# S32K148_M4 register map
Vendor: NXP Semiconductors; File version: 1.1a
CPU: CM4 r0p1, little endian, MPU, FPU, VTOR, 4 interrupt priority bits
Registers are 32-bit, read-write, reset 0x0 unless marked. A register's access mark holds for its fields unless they carry their own. Offsets are from the block's base; [hi:lo] are bit positions; {n}, {i} and the like mark numbered series; 'fields as' and 'values as' point back to an identical list.

## QuadSPI
Base 0x40076000; register names take the prefix QuadSPI_
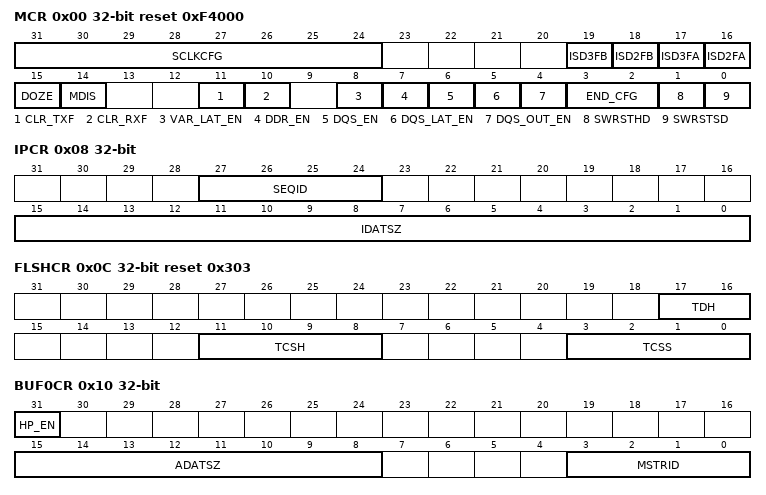
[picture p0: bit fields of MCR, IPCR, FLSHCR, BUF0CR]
0x00 MCR reset 0xF4000 — Module Configuration Register
  [31:24] SCLKCFG — Serial Clock Configuration
  [19] ISD3FB — Idle Signal Drive IOFB[3] Flash B
    0=IOFB[3] is driven to logic L; 1=IOFB[3] is driven to logic H
  [18] ISD2FB — Idle Signal Drive IOFB[2] Flash B
    0=IOFB[2] is driven to logic L; 1=IOFB[2] is driven to logic H
  [17] ISD3FA — Idle Signal Drive IOFA[3] Flash A
    0=IOFA[3] is driven to logic L; 1=IOFA[3] is driven to logic H
  [16] ISD2FA — Idle Signal Drive IOFA[2] Flash A
    0=IOFA[2] is driven to logic L; 1=IOFA[2] is driven to logic H
  [15] DOZE — Doze Enable
    0=A doze request will be ignored by the QuadSPI module; 1=A doze request will be processed by the QuadSPI module
  [14] MDIS — Module Disable
    0=Enable QuadSPI clocks; 1=Allow external logic to disable QuadSPI clocks
  [11] CLR_TXF — Clear TX FIFO/Buffer. Invalidates the TX Buffer content. This is a self-clearing field.
    0=No action; 1=Read and write pointers of the TX Buffer are reset to 0. QSPI_TBSR[TRCTR] is reset to 0.
  [10] CLR_RXF — Clear RX FIFO. Invalidates the RX Buffer. This is a self-clearing field.
    0=No action; 1=Read and write pointers of the RX Buffer are reset to 0. QSPI_RBSR[RDBFL] is reset to 0.
  [8] VAR_LAT_EN — This field is used to enable variable latency feature in the controller
    0=Fixed latency: Twice + 1 latency enable; 1=Variable latency: 'once' or 'twice + 1' the initial latency based on Data strobe during CA phase. If enabled also need to ensure QSPI_FLSHCR[TCSS] must be >= 2.
  [7] DDR_EN — DDR mode enable
    0=2x clock are disabled for SDR instructions only; 1=2x clock are enabled supports both SDR and DDR instruction
  [6] DQS_EN — DQS enable
    0=DQS disabled; 1=DQS enabled. When enabled, the incoming data is sampled on both the edges of DQS input when QSPI_MCR[DDR_EN] is set, else, on only one edge when QSPI_MCR[DDR_EN] is 0. The QSPI_SMPR[DDR_SMP] values are ignored.
  [5] DQS_LAT_EN — DQS Latency Enable
    0=DQS Latency disabled; 1=DQS feature with latency included enabled
  [4] DQS_OUT_EN — This field is valid when Data Strobe is also used as an output from controller during Write data phase
    0=DQS as an output from controller is disabled; 1=DQS as an output from controller is enabled
  [3:2] END_CFG — Defines the endianness of the QuadSPI module. For more details refer to Byte Ordering Endianess
  [1] SWRSTHD — Software reset for AHB domain
    0=No action; 1=AHB domain flops are reset. Does not reset configuration registers. It is advisable to reset both the serial flash domain and AHB domain at the same time. Resetting only one domain might lead to side effects. The software resets need the clock to be running to propagate to the design. The MCR[MDIS] should therefore be set to 0 when the software reset bits are asserted. Also, before they can be deasserted again (by setting MCR[SWRSTHD] to 0), it is recommended to set the MCR[MDIS] bit to 1. Once the software resets have been deasserted, the normal operation can be started by setting the MCR[MDIS] bit to 0.
  [0] SWRSTSD — Software reset for serial flash domain
    0=No action; 1=Serial Flash domain flops are reset. Does not reset configuration registers. It is advisable to reset both the serial flash domain and AHB domain at the same time. Resetting only one domain might lead to side effects. The software resets need the clock to be running to propagate to the design. The MCR[MDIS] should therefore be set to 0 when the software reset bits are asserted. Also, before they can be deasserted again (by setting MCR[SWRSTSD] to 0), it is recommended to set the MCR[MDIS] bit to 1. Once the software resets have been deasserted, the normal operation can be started by setting the MCR[MDIS] bit to 0.
0x08 IPCR — IP Configuration Register
  [27:24] SEQID — Points to a sequence in the Look-up table
  [15:0] IDATSZ — IP data transfer size. Defines the data transfer size in bytes of the IP command.
0x0C FLSHCR reset 0x303 — Flash Configuration Register
  [17:16] TDH — Serial flash data in hold time
    0=Data aligned with the posedge of Internal reference clock of QuadSPI; 1=Data aligned with 2x serial flash half clock
  [11:8] TCSH — Serial flash CS hold time in terms of serial flash clock cycles
  [3:0] TCSS — Serial flash CS setup time in terms of serial flash clock cycles
0x10 BUF0CR — Buffer0 Configuration Register
  [31] HP_EN — High Priority Enable
  [15:8] ADATSZ — AHB data transfer size
  [3:0] MSTRID — Master ID
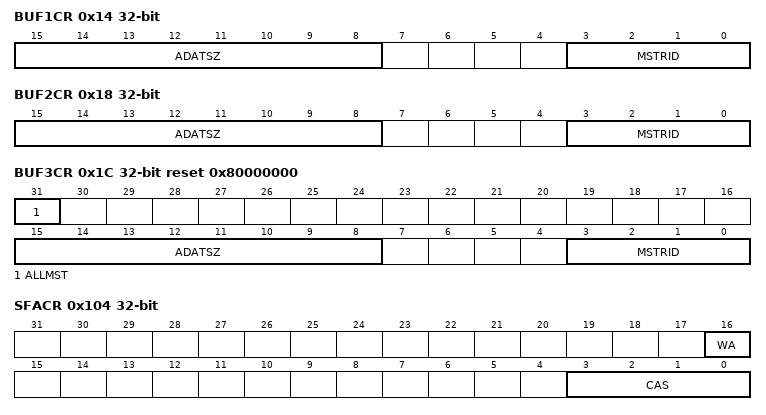
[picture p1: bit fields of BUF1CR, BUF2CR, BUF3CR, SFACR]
0x14 BUF1CR — Buffer1 Configuration Register
  [15:8] ADATSZ — AHB data transfer size
  [3:0] MSTRID — Master ID
0x18 BUF2CR — Buffer2 Configuration Register
  [15:8] ADATSZ — AHB data transfer size
  [3:0] MSTRID — Master ID
0x1C BUF3CR reset 0x80000000 — Buffer3 Configuration Register
  [31] ALLMST — All master enable
  [15:8] ADATSZ — AHB data transfer size
  [3:0] MSTRID — Master ID
0x20 BFGENCR — Buffer Generic Configuration Register
  [15:12] SEQID — Points to a sequence in the Look-up-table
0x24 SOCCR — SOC Configuration Register
  [31:0] SOCCFG — SOC Configuration For details, refer to chip-specific QuadSPI information.
{0x30+4i} BUF{i}IND (i=0..2) — Buffer{i} Top Index Register
  [31:3] TPINDX{i} — Top index of buffer {i}.
0x100 SFAR — Serial Flash Address Register
  [31:0] SFADR — Serial Flash Address. The register content is used as byte address for all following IP Commands.
0x104 SFACR — Serial Flash Address Configuration Register
  [16] WA — Word Addressable
    0=Byte addressable serial flash mode; 1=Word (2 byte) addressable serial flash mode
  [3:0] CAS — Column Address Space
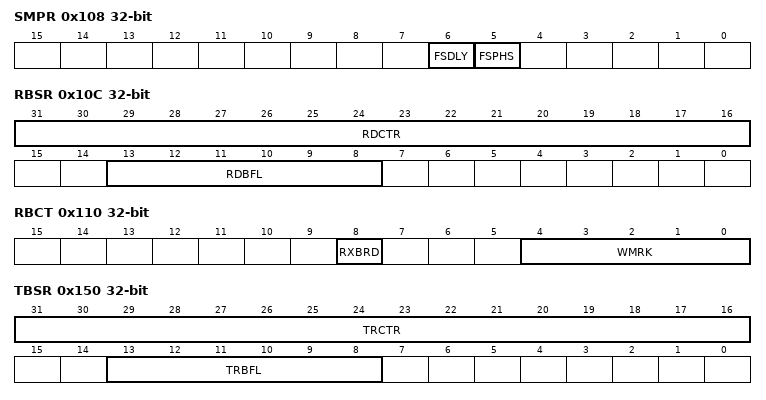
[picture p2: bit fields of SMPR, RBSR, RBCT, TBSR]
0x108 SMPR — Sampling Register
  [6] FSDLY — Full Speed Delay selection for SDR instructions. Select the delay with respect to the reference edge for the sample point valid for full speed commands.
    0=One clock cycle delay; 1=Two clock cycles delay
  [5] FSPHS — Full Speed Phase selection for SDR instructions.
    0=Select sampling at non-inverted clock; 1=Select sampling at inverted clock
0x10C RBSR ro — RX Buffer Status Register
  [31:16] RDCTR — Read Counter
  [13:8] RDBFL — RX Buffer Fill Level
0x110 RBCT — RX Buffer Control Register
  [8] RXBRD — RX Buffer Readout. This field specifies the access scheme for the RX Buffer readout.
    0=RX Buffer content is read using the AHB Bus registers QSPI_ARDB0 to QSPI_ARDB31; 1=RX Buffer content is read using the IP Bus registers QSPI_RBDR0 to QSPI_RBDR31
  [4:0] WMRK — RX Buffer Watermark
0x150 TBSR ro — TX Buffer Status Register
  [31:16] TRCTR — Transmit Counter
  [13:8] TRBFL — TX Buffer Fill Level
0x154 TBDR — TX Buffer Data Register
  [31:0] TXDATA — TX Data On write access the data is written into the next available entry of the TX Buffer and the QPSI_TBSR[TRBFL] field is updated accordingly
0x158 TBCT — Tx Buffer Control Register
  [4:0] WMRK — Determines the watermark for the TX Buffer
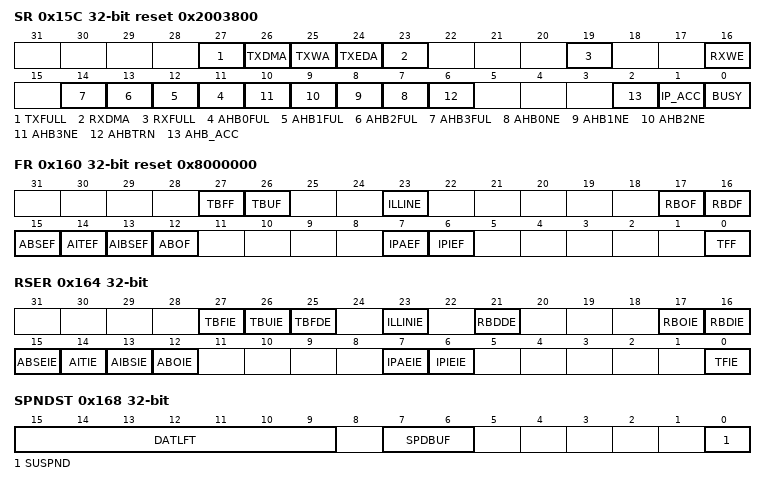
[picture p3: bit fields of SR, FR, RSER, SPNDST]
0x15C SR ro reset 0x2003800 — Status Register
  [27] TXFULL — TX Buffer Full. Asserted when no more data can be stored.
  [26] TXDMA
  [25] TXWA — TX Buffer watermark Available
  [24] TXEDA — Tx Buffer Enough Data Available
  [23] RXDMA — RX Buffer DMA. Asserted when RX Buffer read out via DMA is active i.e DMA is requested or running.
  [19] RXFULL — RX Buffer Full
  [16] RXWE — RX Buffer Watermark Exceeded
  [n+11] AHB{n}FUL (n=0..3) — AHB {n} Buffer Full. Asserted when AHB {n} buffer is full.
  [n+7] AHB{n}NE (n=0..3) — AHB {n} Buffer Not Empty. Asserted when AHB {n} buffer contains data.
  [6] AHBTRN — AHB Access Transaction pending
  [2] AHB_ACC — AHB Access. Asserted when the transaction currently executed was initiated by AHB bus.
  [1] IP_ACC — IP Access. Asserted when transaction currently executed was initiated by IP bus.
  [0] BUSY — Module Busy
0x160 FR reset 0x8000000 write-1-clears — Flag Register
  [27] TBFF write-1-clears — TX Buffer Fill Flag
  [26] TBUF write-1-clears — TX Buffer Underrun Flag
  [23] ILLINE write-1-clears — Illegal Instruction Error Flag
  [17] RBOF write-1-clears — RX Buffer Overflow Flag
  [16] RBDF write-1-clears — RX Buffer Drain Flag
  [15] ABSEF write-1-clears — AHB Sequence Error Flag
  [14] AITEF write-1-clears — AHB Illegal transaction error flag
  [13] AIBSEF write-1-clears — AHB Illegal Burst Size Error Flag
  [12] ABOF write-1-clears — AHB Buffer Overflow Flag
  [7] IPAEF write-1-clears — IP Command Trigger during AHB Access Error Flag
  [6] IPIEF write-1-clears — IP Command Trigger could not be executed Error Flag
  [0] TFF write-1-clears — IP Command Transaction Finished Flag
0x164 RSER — Interrupt and DMA Request Select and Enable Register
  [27] TBFIE — TX Buffer Fill Interrupt Enable
    0=No TBFF interrupt will be generated; 1=TBFF interrupt will be generated
  [26] TBUIE — TX Buffer Underrun Interrupt Enable
    0=No TBUF interrupt will be generated; 1=TBUF interrupt will be generated
  [25] TBFDE — TX Buffer Fill DMA Enable
    0=No DMA request will be generated; 1=DMA request will be generated
  [23] ILLINIE — Illegal Instruction Error Interrupt Enable. Triggered by ILLINE flag in QSPI_FR
    0=No ILLINE interrupt will be generated; 1=ILLINE interrupt will be generated
  [21] RBDDE — RX Buffer Drain DMA Enable: Enables generation of DMA requests for RX Buffer Drain
    values as TBFDE
  [17] RBOIE — RX Buffer Overflow Interrupt Enable
    0=No RBOF interrupt will be generated; 1=RBOF interrupt will be generated
  [16] RBDIE — RX Buffer Drain Interrupt Enable: Enables generation of IRQ requests for RX Buffer Drain
    0=No RBDF interrupt will be generated; 1=RBDF Interrupt will be generated
  [15] ABSEIE — AHB Sequence Error Interrupt Enable: Triggered by ABSEF flags of QSPI_FR
    0=No ABSEF interrupt will be generated; 1=ABSEF interrupt will be generated
  [14] AITIE — AHB Illegal transaction interrupt enable.
    0=No AITEF interrupt will be generated; 1=AITEF interrupt will be generated
  [13] AIBSIE — AHB Illegal Burst Size Interrupt Enable
    0=No AIBSEF interrupt will be generated; 1=AIBSEF interrupt will be generated
  [12] ABOIE — AHB Buffer Overflow Interrupt Enable
    0=No ABOF interrupt will be generated; 1=ABOF interrupt will be generated
  [7] IPAEIE — IP Command Trigger during AHB Access Error Interrupt Enable
    0=No IPAEF interrupt will be generated; 1=IPAEF interrupt will be generated
  [6] IPIEIE — IP Command Trigger during IP Access Error Interrupt Enable
    0=No IPIEF interrupt will be generated; 1=IPIEF interrupt will be generated
  [0] TFIE — Transaction Finished Interrupt Enable
    0=No TFF interrupt will be generated; 1=TFF interrupt will be generated
0x168 SPNDST ro — Sequence Suspend Status Register
  [15:9] DATLFT — Data left: Provides information about the amount of data left to be read in the suspended sequence
  [7:6] SPDBUF — Suspended Buffer: Provides the suspended buffer number. Valid only when SUSPND is set to 1'b1
  [0] SUSPND — When set, it signifies that a sequence is in suspended state
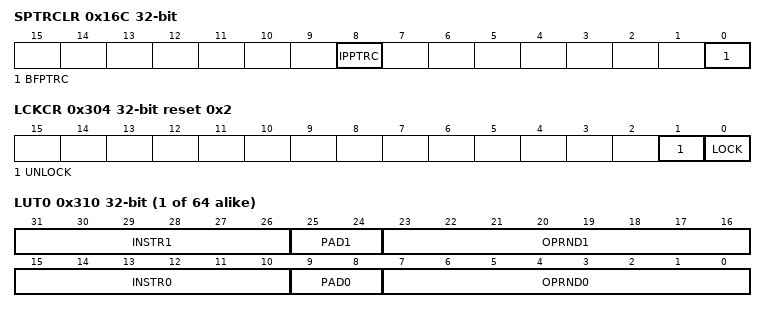
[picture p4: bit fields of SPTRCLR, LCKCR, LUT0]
0x16C SPTRCLR — Sequence Pointer Clear Register
  [8] IPPTRC — IP Pointer Clear: 1: Clears the sequence pointer for IP accesses as defined in QuadSPI_IPCR This is a self-clearing field
  [0] BFPTRC — Buffer Pointer Clear: 1: Clears the sequence pointer for AHB accesses as defined in QuadSPI_BFGENCR
0x180 SFA1AD — Serial Flash A1 Top Address
  [31:10] TPADA1 — Top address for Serial Flash A1. In effect, TPADxx is the first location of the next memory.
0x184 SFA2AD — Serial Flash A2 Top Address
  [31:10] TPADA2 — Top address for Serial Flash A2. In effect, TPxxAD is the first location of the next memory.
0x188 SFB1AD — Serial Flash B1 Top Address
  [31:10] TPADB1 — Top address for Serial Flash B1.In effect, TPxxAD is the first location of the next memory.
0x18C SFB2AD — Serial Flash B2 Top Address
  [31:10] TPADB2 — Top address for Serial Flash B2. In effect, TPxxAD is the first location of the next memory.
{0x200+4i} RBDR{i} (i=0..31) ro — RX Buffer Data Register
  [31:0] RXDATA
0x300 LUTKEY reset 0x5AF05AF0
  [31:0] KEY — The key to lock or unlock the LUT. The KEY is 0x5AF05AF0. The read value is always 0x5AF05AF0
0x304 LCKCR reset 0x2 — LUT Lock Configuration Register
  [1] UNLOCK — Unlocks the LUT when the following two conditions are met: 1
  [0] LOCK — Locks the LUT when the following condition is met: This register is written just after the LUTKEYLUT Key Register The LUT key register was written with 0x5AF05AF0 key
{0x310+4i} LUT{i} (i=0..63) — Look-up Table register
  [31:26] INSTR1 — Instruction 1
  [25:24] PAD1 — Pad information for INSTR1.
    0=1 Pad; 1=2 Pads; 2=4 Pads; 3=8 Pads
  [23:16] OPRND1 — Operand for INSTR1.
  [15:10] INSTR0 — Instruction 0
  [9:8] PAD0 — Pad information for INSTR0.
    0=1 Pad; 1=2 Pads; 2=4 Pads; 3=8 Pads
  [7:0] OPRND0 — Operand for INSTR0.
